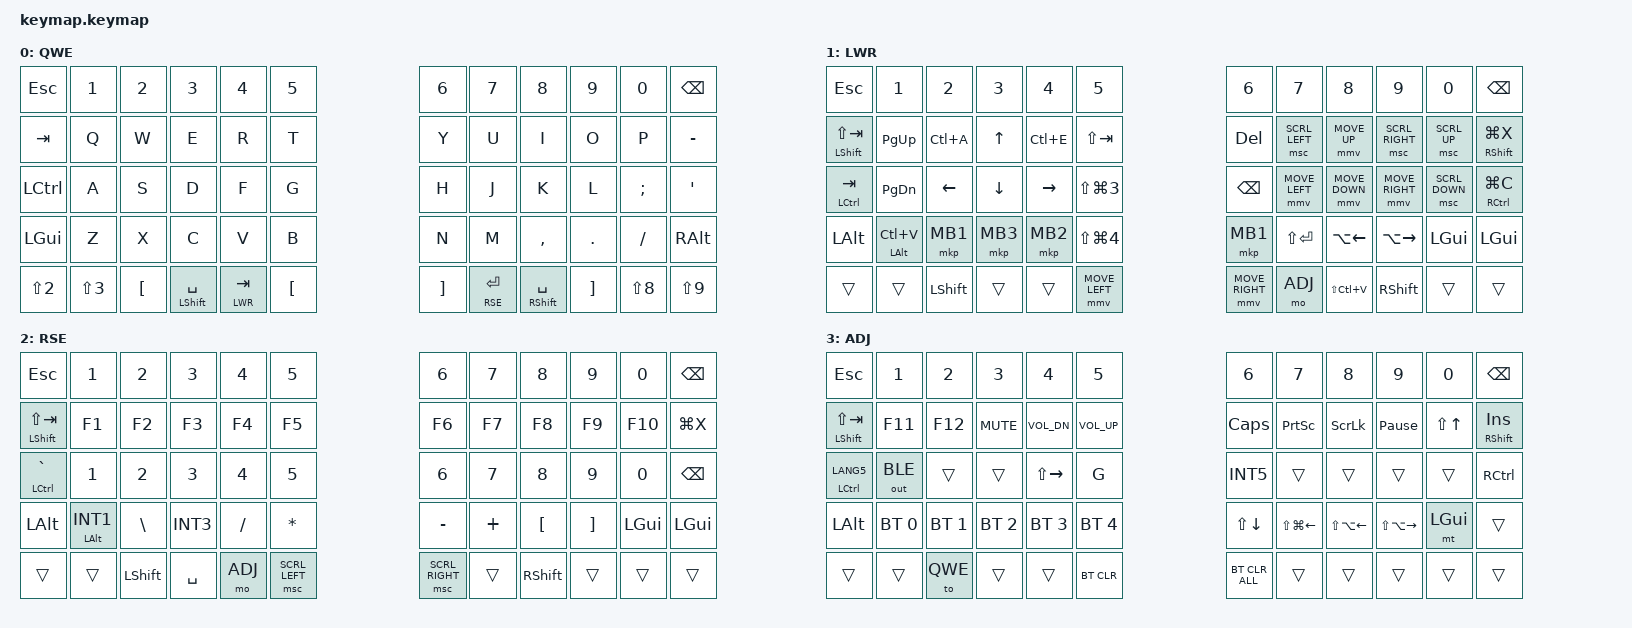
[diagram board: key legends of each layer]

#include <behaviors.dtsi>
#include <dt-bindings/zmk/keys.h>
#include <dt-bindings/zmk/bt.h>
#include <dt-bindings/zmk/mouse.h>
#include <dt-bindings/zmk/outputs.h>
#include <dt-bindings/zmk/pointing.h>

#define QWE 0
#define LWR 1
#define RSE 2
#define ADJ 3


/ {
    keymap {
        compatible = "zmk,keymap";

        QWE {
            bindings = <
            // +---------------+---------------+---------------+---------------+---------------+---------------+---------------+---------------+---------------+---------------+---------------+---------------+---------------+---------------
                &kp ESC         &kp N1          &kp N2          &kp N3          &kp N4          &kp N5                                          &kp N6          &kp N7          &kp N8          &kp N9          &kp N0          &kp BSPC
                &kp TAB         &kp Q           &kp W           &kp E           &kp R           &kp T                                           &kp Y           &kp U           &kp I           &kp O           &kp P           &kp MINUS
                &kp LCTRL       &kp A           &kp S           &kp D           &kp F           &kp G                                           &kp H           &kp J           &kp K           &kp L           &kp SEMI        &kp SQT
                &kp LGUI        &kp Z           &kp X           &kp C           &kp V           &kp B                                           &kp N           &kp M           &kp COMMA       &kp DOT         &kp SLASH       &kp RALT
                                &kp LS(N2)      &kp LS(N3)      &kp LBKT        &mt LSHFT SPACE &lt LWR TAB     &kp LBKT        &kp RBKT        &lt RSE ENTER   &mt RSHFT SPACE &kp RBKT        &kp LS(N8)      &kp LS(N9)
            >;
        };

        LWR {
            bindings = <
            // +---------------+---------------+---------------+---------------+---------------+---------------+---------------+---------------+---------------+---------------+---------------+---------------+---------------+---------------
                &kp ESC         &kp N1          &kp N2          &kp N3          &kp N4          &kp N5                                          &kp N6          &kp N7          &kp N8          &kp N9          &kp N0          &kp BSPC
                &mt LSHFT LS(TAB) &kp PG_UP     &kp LC(A)       &kp UP          &kp LC(E)       &kp LS(TAB)                                     &kp DEL         &msc SCRL_LEFT  &mmv MOVE_UP    &msc SCRL_RIGHT &msc SCRL_UP    &mt RSHFT LG(X)
                &mt LCTRL TAB   &kp PG_DN       &kp LEFT        &kp DOWN        &kp RIGHT       &kp LS(LG(N3))                                  &kp BSPC        &mmv MOVE_LEFT  &mmv MOVE_DOWN  &mmv MOVE_RIGHT &msc SCRL_DOWN  &mt RCTRL LG(C)
                &kp LALT        &mt LALT LC(V)  &mkp MB1        &mkp MB3        &mkp MB2        &kp LS(LG(N4))                                  &mkp MB1        &kp LS(ENTER)   &kp LA(LEFT)    &kp LA(RIGHT)   &kp LGUI        &kp LGUI       
                                &trans          &trans          &kp LSHFT       &trans          &trans          &mmv MOVE_LEFT  &mmv MOVE_RIGHT &mo ADJ         &kp LS(LC(V))   &kp RSHFT       &trans          &trans

            >;
        };

        RSE {
            bindings = <
            // +---------------+---------------+---------------+---------------+---------------+---------------+---------------+---------------+---------------+---------------+---------------+---------------+---------------+---------------
                &kp ESC         &kp N1          &kp N2          &kp N3          &kp N4          &kp N5                                          &kp N6          &kp N7          &kp N8          &kp N9          &kp N0          &kp BSPC
                &mt LSHFT LS(TAB) &kp F1        &kp F2          &kp F3          &kp F4          &kp F5                                          &kp F6          &kp F7          &kp F8          &kp F9          &kp F10         &kp LG(X)
                &mt LCTRL GRAVE &kp N1          &kp N2          &kp N3          &kp N4          &kp N5                                          &kp N6          &kp N7          &kp N8          &kp N9          &kp N0          &kp BSPC
                &kp LALT        &mt LALT INT1   &kp BSLH        &kp INT3        &kp SLASH       &kp ASTRK                                       &kp MINUS       &kp PLUS        &kp LBKT        &kp RBKT        &kp LGUI        &kp LGUI
                                &trans          &trans          &kp LSHFT       &kp SPACE       &mo ADJ         &msc SCRL_LEFT  &msc SCRL_RIGHT &trans          &kp RSHFT       &trans          &trans          &trans
            >;
        };

        ADJ {
            bindings = <
            // +---------------+---------------+---------------+---------------+---------------+---------------+---------------+---------------+---------------+---------------+---------------+---------------+---------------+---------------
                &kp ESC         &kp N1          &kp N2          &kp N3          &kp N4          &kp N5                                          &kp N6          &kp N7          &kp N8          &kp N9          &kp N0          &kp BSPC
                &mt LSHFT LS(TAB) &kp F11       &kp F12         &kp C_MUTE      &kp C_VOL_DN    &kp C_VOL_UP                                    &kp CAPS        &kp PSCRN      	&kp SLCK        &kp PAUSE_BREAK &kp LS(UP)      &mt RSHFT INS
                &mt LCTRL LANG5 &out OUT_BLE    &trans          &trans          &kp LS(RIGHT)   &kp G                                           &kp INT5        &trans          &trans          &trans          &trans    		&kp RCTRL
                &kp LALT        &bt BT_SEL 0    &bt BT_SEL 1    &bt BT_SEL 2    &bt BT_SEL 3    &bt BT_SEL 4                                    &kp LS(DOWN) &kp LS(LG(LEFT)) &kp LS(LA(LEFT)) &kp LS(LA(RIGHT)) &mt LGUI       &trans
                                &trans          &trans          &to QWE         &trans          &trans          &bt BT_CLR      &bt BT_CLR_ALL  &trans          &trans	        &trans          &trans          &trans
            >;
        };
    };
};
